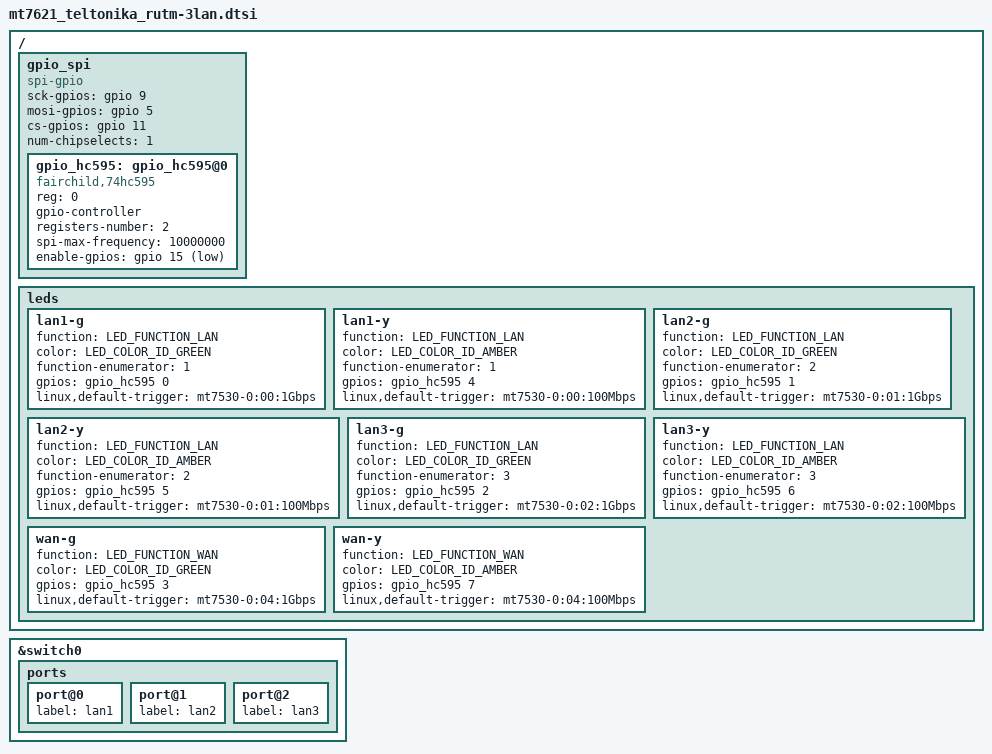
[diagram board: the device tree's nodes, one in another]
// SPDX-License-Identifier: GPL-2.0-or-later OR MIT

#include "mt7621_teltonika_rutm-common.dtsi"

/ {
	gpio_spi {
		compatible = "spi-gpio";
		#address-cells = <1>;
		#size-cells = <0>;

		sck-gpios = <&gpio 9 GPIO_ACTIVE_HIGH>;
		mosi-gpios = <&gpio 5 GPIO_ACTIVE_HIGH>;
		cs-gpios = <&gpio 11 GPIO_ACTIVE_HIGH>;
		num-chipselects = <1>;

		gpio_hc595: gpio_hc595@0 {
			compatible = "fairchild,74hc595";
			reg = <0>;
			gpio-controller;
			#gpio-cells = <2>;
			registers-number = <2>;
			spi-max-frequency = <10000000>;
			enable-gpios = <&gpio 15 GPIO_ACTIVE_LOW>;
		};
	};

	leds {
		lan1-g {
			function = LED_FUNCTION_LAN;
			color = <LED_COLOR_ID_GREEN>;
			function-enumerator = <1>;
			gpios = <&gpio_hc595 0 GPIO_ACTIVE_HIGH>;
			linux,default-trigger = "mt7530-0:00:1Gbps";
		};

		lan1-y {
			function = LED_FUNCTION_LAN;
			color = <LED_COLOR_ID_AMBER>;
			function-enumerator = <1>;
			gpios = <&gpio_hc595 4 GPIO_ACTIVE_HIGH>;
			linux,default-trigger = "mt7530-0:00:100Mbps";
		};

		lan2-g {
			function = LED_FUNCTION_LAN;
			color = <LED_COLOR_ID_GREEN>;
			function-enumerator = <2>;
			gpios = <&gpio_hc595 1 GPIO_ACTIVE_HIGH>;
			linux,default-trigger = "mt7530-0:01:1Gbps";
		};

		lan2-y {
			function = LED_FUNCTION_LAN;
			color = <LED_COLOR_ID_AMBER>;
			function-enumerator = <2>;
			gpios = <&gpio_hc595 5 GPIO_ACTIVE_HIGH>;
			linux,default-trigger = "mt7530-0:01:100Mbps";
		};

		lan3-g {
			function = LED_FUNCTION_LAN;
			color = <LED_COLOR_ID_GREEN>;
			function-enumerator = <3>;
			gpios = <&gpio_hc595 2 GPIO_ACTIVE_HIGH>;
			linux,default-trigger = "mt7530-0:02:1Gbps";
		};

		lan3-y {
			function = LED_FUNCTION_LAN;
			color = <LED_COLOR_ID_AMBER>;
			function-enumerator = <3>;
			gpios = <&gpio_hc595 6 GPIO_ACTIVE_HIGH>;
			linux,default-trigger = "mt7530-0:02:100Mbps";
		};

		wan-g {
			function = LED_FUNCTION_WAN;
			color = <LED_COLOR_ID_GREEN>;
			gpios = <&gpio_hc595 3 GPIO_ACTIVE_HIGH>;
			linux,default-trigger = "mt7530-0:04:1Gbps";
		};

		wan-y {
			function = LED_FUNCTION_WAN;
			color = <LED_COLOR_ID_AMBER>;
			gpios = <&gpio_hc595 7 GPIO_ACTIVE_HIGH>;
			linux,default-trigger = "mt7530-0:04:100Mbps";
		};
	};
};

&switch0 {
	ports {
		port@0 {
			status = "okay";
			label = "lan1";
		};

		port@1 {
			status = "okay";
			label = "lan2";
		};

		port@2 {
			status = "okay";
			label = "lan3";
		};
	};
};
